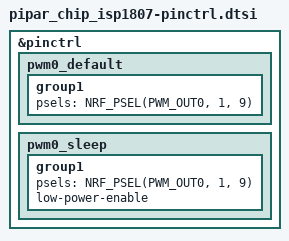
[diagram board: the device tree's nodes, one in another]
&pinctrl {
    pwm0_default: pwm0_default {
        group1 {
            psels = <NRF_PSEL(PWM_OUT0, 1, 9)>;
        };
    };

    pwm0_sleep: pwm0_sleep {
        group1 {
            psels = <NRF_PSEL(PWM_OUT0, 1, 9)>;
            low-power-enable;
        };
    };
};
